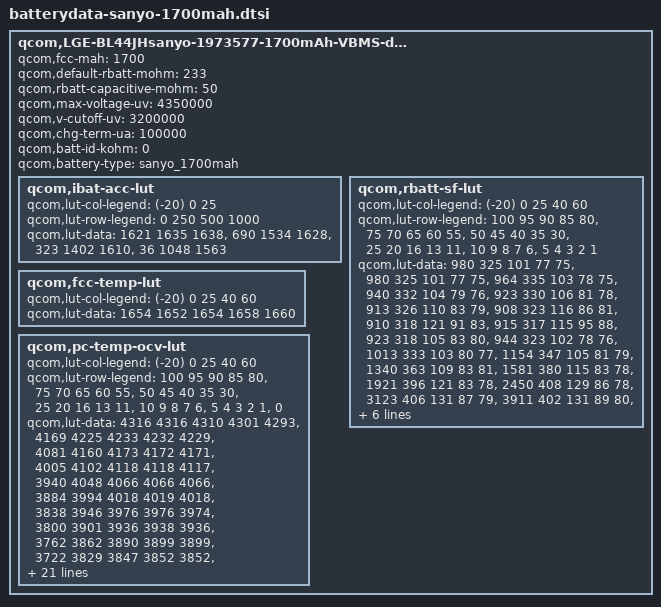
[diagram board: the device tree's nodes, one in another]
/* Copyright (c) 2013-2014, The Linux Foundation. All rights reserved.
 *
 * This program is free software; you can redistribute it and/or modify
 * it under the terms of the GNU General Public License version 2 and
 * only version 2 as published by the Free Software Foundation.
 *
 * This program is distributed in the hope that it will be useful,
 * but WITHOUT ANY WARRANTY; without even the implied warranty of
 * MERCHANTABILITY or FITNESS FOR A PARTICULAR PURPOSE.  See the
 * GNU General Public License for more details.
 */

qcom,LGE-BL44JHsanyo-1973577-1700mAh-VBMS-data {
	qcom,fcc-mah = <1700>;
	qcom,default-rbatt-mohm = <233>;
	qcom,rbatt-capacitive-mohm = <50>;
	qcom,max-voltage-uv = <4350000>;
	qcom,v-cutoff-uv = <3200000>;
	qcom,chg-term-ua = <100000>;
	qcom,batt-id-kohm = <0>;
	qcom,battery-type = "sanyo_1700mah";

	qcom,ibat-acc-lut {
		qcom,lut-col-legend = <(-20) 0 25>;
		qcom,lut-row-legend = <0 250 500 1000>;
		qcom,lut-data = <1621 1635 1638>,
				<690 1534 1628>,
				<323 1402 1610>,
				<36 1048 1563>;
	};

	qcom,rbatt-sf-lut {
		qcom,lut-col-legend = <(-20) 0 25 40 60>;
		qcom,lut-row-legend = <100 95 90 85 80>,
				<75 70 65 60 55>,
				<50 45 40 35 30>,
				<25 20 16 13 11>,
				<10 9 8 7 6>,
				<5 4 3 2 1>;
		qcom,lut-data = <980 325 101 77 75>,
				<980 325 101 77 75>,
				<964 335 103 78 75>,
				<940 332 104 79 76>,
				<923 330 106 81 78>,
				<913 326 110 83 79>,
				<908 323 116 86 81>,
				<910 318 121 91 83>,
				<915 317 115 95 88>,
				<923 318 105 83 80>,
				<944 323 102 78 76>,
				<1013 333 103 80 77>,
				<1154 347 105 81 79>,
				<1340 363 109 83 81>,
				<1581 380 115 83 78>,
				<1921 396 121 83 78>,
				<2450 408 129 86 78>,
				<3123 406 131 87 79>,
				<3911 402 131 89 80>,
				<4738 422 137 92 82>,
				<5314 437 138 94 83>,
				<6021 457 138 96 83>,
				<6759 464 130 96 86>,
				<7967 473 123 97 87>,
				<10158 518 124 95 87>,
				<13593 589 122 90 84>,
				<19449 770 119 88 86>,
				<30735 1255 121 90 87>,
				<53762 2372 130 94 90>,
				<92793 4744 150 105 111>;
	};

	qcom,fcc-temp-lut {
		qcom,lut-col-legend = <(-20) 0 25 40 60>;
		qcom,lut-data = <1654 1652 1654 1658 1660>;
	};

	qcom,pc-temp-ocv-lut {
		qcom,lut-col-legend = <(-20) 0 25 40 60>;
		qcom,lut-row-legend = <100 95 90 85 80>,
				<75 70 65 60 55>,
				<50 45 40 35 30>,
				<25 20 16 13 11>,
				<10 9 8 7 6>,
				<5 4 3 2 1>,
				<0>;
		qcom,lut-data = <4316 4316 4310 4301 4293>,
				<4169 4225 4233 4232 4229>,
				<4081 4160 4173 4172 4171>,
				<4005 4102 4118 4118 4117>,
				<3940 4048 4066 4066 4066>,
				<3884 3994 4018 4019 4018>,
				<3838 3946 3976 3976 3974>,
				<3800 3901 3936 3938 3936>,
				<3762 3862 3890 3899 3899>,
				<3722 3829 3847 3852 3852>,
				<3688 3803 3818 3821 3821>,
				<3660 3786 3797 3800 3800>,
				<3636 3772 3782 3785 3784>,
				<3613 3759 3772 3772 3772>,
				<3590 3744 3764 3762 3754>,
				<3564 3723 3752 3748 3735>,
				<3533 3689 3728 3726 3714>,
				<3503 3642 3695 3696 3686>,
				<3476 3595 3666 3670 3662>,
				<3454 3567 3651 3659 3654>,
				<3441 3554 3642 3652 3648>,
				<3428 3541 3631 3644 3640>,
				<3414 3527 3616 3634 3630>,
				<3399 3511 3594 3619 3616>,
				<3380 3491 3570 3594 3590>,
				<3358 3462 3538 3554 3543>,
				<3330 3423 3486 3495 3480>,
				<3292 3371 3416 3422 3403>,
				<3236 3300 3328 3328 3302>,
				<3144 3194 3200 3192 3158>,
				<3000 3000 3000 3000 3000>;
	};
};
